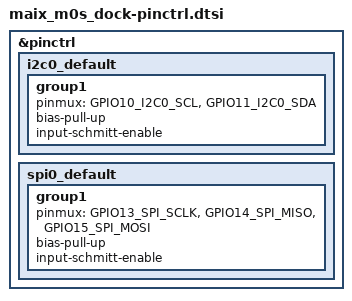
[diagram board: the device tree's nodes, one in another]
/*
 * Copyright (c) 2025 MASSDRIVER EI (massdriver.space)
 *
 * SPDX-License-Identifier: Apache-2.0
 */

&pinctrl {
	i2c0_default: i2c0_default {
		group1 {
			pinmux = <GPIO10_I2C0_SCL>,
				 <GPIO11_I2C0_SDA>;
			bias-pull-up;
			input-schmitt-enable;
		};
	};

	spi0_default: spi0_default {
		group1 {
			pinmux = <GPIO13_SPI_SCLK>,
				 <GPIO14_SPI_MISO>,
				 <GPIO15_SPI_MOSI>;
			bias-pull-up;
			input-schmitt-enable;
		};
	};
};
